# FX1 register map
Vendor: FTEL; File version: VP_FX1_V3.0_ISP_1.07
Registers are 32-bit, read-write, reset 0x0 unless marked. A register's access mark holds for its fields unless they carry their own. Offsets are from the block's base; [hi:lo] are bit positions; lines under a group give offsets from that group; {n}, {i} and the like mark numbered series; 'fields as' and 'values as' point back to an identical list.

## ISP (part 3 of 4) — ISP FX1 v1.07; đủ register/field từ sheet Flat Registers của CSR. Địa chỉ base theo BSP VP_FX1_V3.0; không thay thế xác nhận map silicon.
Base 0x11000000
0x2604 AF_ZONE_EN reset 0xFFFF — AF: focus zone mask (not implemented). The frame is divided into a 4x4 grid of zones; all sixteen zones always contribute. [access=rw]
  [15:0] ZONE_EN — Focus Zone Enable Mask (not implemented) No hardware behind this field; every zone is measured. One bit per focus zone, 4x4 grid in raster order. Reset enables all sixteen. bit 0 = ZONE_0 (Row 0, column 0) bit 1 = ZONE_1 (Row 0, column 1) bit 2 = ZONE_2 (Row 0, column 2) bit 3 = ZONE_3 (Row 0, column 3) bit 4 = ZONE_4 (Row 1, column 0) bit 5 = ZONE_5 (Row 1, column 1) bit 6 = ZONE_6 (Row 1, column 2) bit 7 = ZONE_7 (Row 1, column 3) bit 8 = ZONE_8 (Row 2, column 0) bit 9 = ZONE_9 (Row 2, column 1) bit 10 = ZONE_10 (Row 2, column 2) bit 11 = ZONE_11 (Row 2, column 3) bit 12 = ZONE_12 (Row 3, column 0) bit 13 = ZONE_13 (Row 3, column 1) bit 14 = ZONE_14 (Row 3, column 2) bit 15 = ZONE_15 (Row 3, column 3) [access=rw]
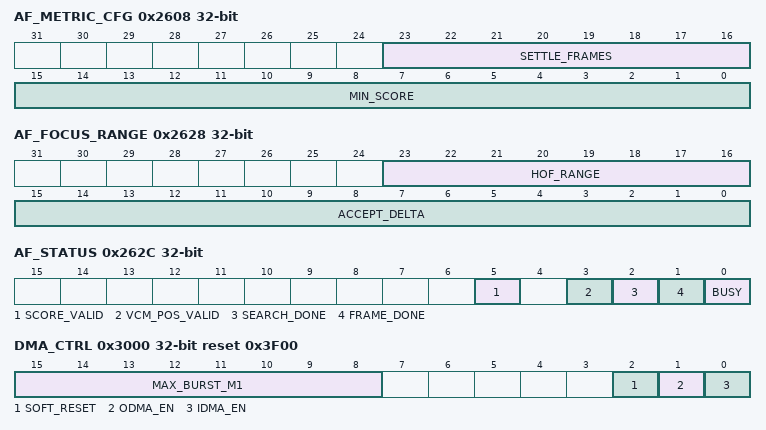
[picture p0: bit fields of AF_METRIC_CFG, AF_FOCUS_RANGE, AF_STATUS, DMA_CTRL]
0x2608 AF_METRIC_CFG — AF_METRIC_CFG: reserved autofocus search/lens-control field. This MAS provides per-zone focus measurements only; lens movement and search are software functions. [access=rw]
  [23:16] SETTLE_FRAMES — VCM Settling Frames (not implemented) Reserved; no processing effect in this MAS. [access=rw]
  [15:0] MIN_SCORE — Minimum Valid Focus Score (not implemented) Reserved; no processing effect in this MAS. [access=rw]
0x260C AF_STAT_ADDR — AF: which zone AF_STAT_DATA reports. [access=rw]
  [3:0] ZONE_ADDR — Readout Zone Select Zone index 0..15, raster order. [access=rw]
0x2610 AF_STAT_DATA ro — AF: low 32 bits of the selected focus sum from the leased result bank. Use the 64-bit port when the full value is needed. Higher scores indicate more local detail, not an absolute focus distance. [access=ro]
  [31:0] FOCUS_SCORE — Zone Focus Score Low 32 bits of the authoritative 64-bit focus sum selected by AF_STAT_ADDR. ACQUIRE before reading and RELEASE after copying; no lease returns zero and sets NO_LEASE. [access=ro]
0x2614 AF_LUT_ADDR — AF_LUT_ADDR: reserved autofocus search/lens-control field. This MAS provides per-zone focus measurements only; lens movement and search are software functions. [access=rw]
  [7:0] LUT_ADDR — Position LUT Index (not implemented) Reserved; no processing effect in this MAS. [access=rw]
0x2618 AF_LUT_DATA — AF_LUT_DATA: reserved autofocus search/lens-control field. This MAS provides per-zone focus measurements only; lens movement and search are software functions. [access=rw]
  [15:0] VCM_POSITION — Position LUT Data (not implemented) Reserved; no processing effect in this MAS. [access=rw]
0x261C AF_VCM_CUR_POS — AF_VCM_CUR_POS: reserved autofocus search/lens-control field. This MAS provides per-zone focus measurements only; lens movement and search are software functions. [access=rw]
  [15:0] VCM_CUR_POS — Current VCM Position (not implemented) Reserved; no processing effect in this MAS. Software that drives a VCM itself can still use it as a scratch tag. [access=rw]
0x2620 AF_VCM_BEST_POS ro — AF_VCM_BEST_POS: reserved autofocus search/lens-control field. This MAS provides per-zone focus measurements only; lens movement and search are software functions. [access=ro]
  [15:0] VCM_BEST_POS — Best VCM Position (not implemented) Reserved; no processing effect in this MAS. [access=ro]
0x2624 AF_PEAK_SCORE ro — AF_PEAK_SCORE: reserved autofocus search/lens-control field. This MAS provides per-zone focus measurements only; lens movement and search are software functions. [access=ro]
  [31:0] PEAK_SCORE — Peak Focus Score (not implemented) Reserved; no processing effect in this MAS. [access=ro]
0x2628 AF_FOCUS_RANGE — AF_FOCUS_RANGE: reserved autofocus search/lens-control field. This MAS provides per-zone focus measurements only; lens movement and search are software functions. [access=rw]
  [23:16] HOF_RANGE — Hyperfocal Range (not implemented) Reserved; no processing effect in this MAS. [access=rw]
  [15:0] ACCEPT_DELTA — Acceptable Focus Delta (not implemented) Reserved; no processing effect in this MAS. [access=rw]
0x262C AF_STATUS — AF: measurement status. BUSY reports in-flight accumulation, FRAME_DONE is a sticky W1C completion event, and SCORE_VALID identifies published scores. Search-related fields are reserved. [access=mixed]
  [5] SCORE_VALID ro — Focus Scores Valid 1 = the published scores are from a completed frame. [access=ro]
  [3] VCM_POS_VALID write-1-clears — VCM Position Valid (not implemented) Reserved; no processing effect in this MAS. [access=w1c]
  [2] SEARCH_DONE write-1-clears — Search Complete (not implemented) Reserved; no processing effect in this MAS. [access=w1c]
  [1] FRAME_DONE write-1-clears — Focus Scores Ready Set when a frame's focus scores are complete. Write 1 to clear. [access=w1c]
  [0] BUSY ro — AF Statistics Busy 1 = a frame is being accumulated. [access=ro]
0x2630 AF_CONTEXT_ID — AF: software lens-position context tag captured with the completed statistics frame. [access=rw]
  [31:0] CONTEXT_ID — Statistics Context Tag Arbitrary software value, captured with the frame that is measured next. Exposure and lens changes take effect some frames after they are requested, so the tag is how software tells which request a result belongs to: write it here before the frame it describes, and read it back from AF_RESULT_CONTEXT_ID alongside that frame's statistics. [access=rw]
0x2634 AF_RESULT_CONTEXT_ID ro — AF: software context tag published with the leased statistics frame; stable until RELEASE. [access=ro]
  [31:0] CONTEXT_ID — Captured Statistics Context Tag AF_CONTEXT_ID captured at ingress for the leased statistics frame. Stable until RELEASE, including when another frame completes. No lease returns zero and sets NO_LEASE. [access=ro]
0x2638 AF_FRAME_ID ro — AF: ingress frame identifier of the leased result bank, read-only. [access=ro]
  [31:0] FRAME_ID — Shared ingress-SOF frame number of the leased statistics. First admitted frame after hard reset is 1; wraps modulo 2^32. Common and DMA soft resets preserve the counter. Metadata remains stable until RELEASE; no lease returns zero and sets the ownership error. [access=ro]
0x2800 OFMT_CTRL — Output Formatter control. In the integrated core the formatter padding input is tied to zero: STRIDE_EN, OFMT_Y_STRIDE and OFMT_UV_STRIDE are readable storage with no effect, and ODMA alone applies the line stride. [access=rw]
  [0] STRIDE_EN — Line Stride Padding Enable Storage only in the integrated core; lines are always emitted packed and the ODMA applies the stride. Padding up to OFMT_Y_STRIDE / OFMT_UV_STRIDE is a standalone formatter capability. [access=rw]
0x2804 OFMT_Y_STRIDE reset 0xF00 — Output Formatter: luma line stride in bytes. Storage only in the integrated core (see OFMT_CTRL). [access=rw]
  [15:0] Y_STRIDE — Luma Line Stride Bytes from one luma line to the next, one byte per pixel. A value at or below the active width emits no padding. [access=rw]
0x2808 OFMT_UV_STRIDE reset 0xF00 — Output Formatter: chroma line stride in bytes. Storage only in the integrated core (see OFMT_CTRL). [access=rw]
  [15:0] UV_STRIDE — Chroma Line Stride Bytes from one chroma line to the next. Padding is emitted as 16-bit beats, so an odd byte count rounds down. [access=rw]
0x3000 DMA_CTRL reset 0x3F00 — DMA Engine: control at byte offset 0x3000. Configure and enable the pixel pipeline before arming/enabling DMA so output geometry is valid. DMA and CSR transactions are independent. [access=mixed]
  [15:8] MAX_BURST_M1 — Maximum AXI Burst Length Minus One Encoded value 0..255 gives 1..256 beats. Reset 63 gives 64 beats. MAX_BURST_BEATS in the MAS is the effective value MAX_BURST_M1+1; bursts also split at line and 4 KiB boundaries. [access=rw]
  [2] SOFT_RESET wo write-1-sets — DMA Soft Reset Request DMA-scope group recovery: stop admission, drain both AXI masters, held requests and internal consumers, then 15-clock internal reset pulse; reads zero. Preserves CSR configuration, the sealed active profile, completed READY/LEASED statistics and the DONE bits and metadata of outputs completed before the request. Preserves DMA_ERR and DMA_IRQ_STAT. Clears VALID/FREE ownership and restarts every rotation at buffer 0. Poll COMMON_RECOVERY_STATUS.BUSY/DONE; copy abort records before restart. Busy requests rejected with TUNE_ERROR.PENDING. COMMON_CTRL.SOFT_RST has the broader pipeline/result reset scope. [access=w1p]
  [1] ODMA_EN — Output DMA Enable 1 = the output DMA writes frames to DDR. [access=rw]
  [0] IDMA_EN — Input Enable 1 = the input path admits frames: the input DMA fetches frames from DDR (INPUT_SRC_CTRL.SEL = 0) or the AXI4-Stream adapter accepts frames from the stream port (SEL = 1). [access=rw]
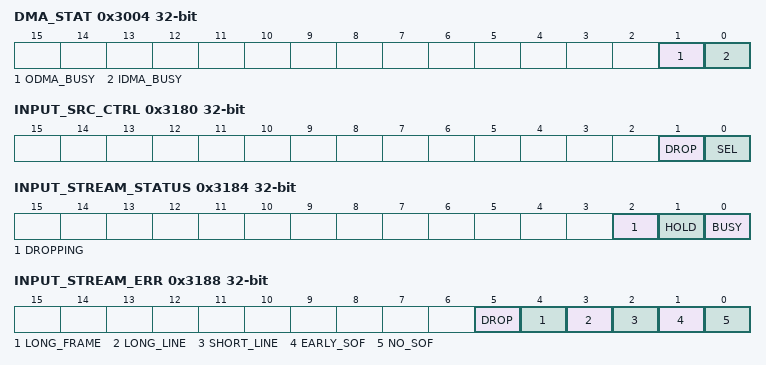
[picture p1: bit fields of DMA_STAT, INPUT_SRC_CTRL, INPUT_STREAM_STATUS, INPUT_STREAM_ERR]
0x3004 DMA_STAT ro — DMA Engine: engine status, read-only. Both bits read 0 on a wedged engine as well as an idle one, so do not treat 0 here as proof the engine is healthy -- check the frame counters advance. [access=ro]
  [1] ODMA_BUSY — Output DMA Busy 1 = the output DMA has a transfer outstanding. [access=ro]
  [0] IDMA_BUSY — Input Busy 1 = the input DMA has a transfer outstanding, or the AXI4-Stream adapter is forwarding a frame (SEL = 1). [access=ro]
0x3008 DMA_ERR write-1-clears — DMA Engine: sticky error flags. Write 1 to clear. Sticky so a fault that occurred mid-frame survives until software looks. [access=w1c]
  [5:0] ERR write-1-clears — Sticky DMA Error Flags W1C, hardware set wins over simultaneous clear. DMA-scope recovery, automatic or commanded, preserves these bits; only W1C, common recovery and hard reset clear them. Bit 0 ALIGN: illegal address/stride alignment or geometry, a base-address bit at or above the build address width, or a plane whose last byte reaches 2^ADDR_W; checked at IDMA frame start and ODMA buffer claim. The buffer is not used, its ownership bit clears and the rotation does not advance. Bit 1 IDMA_UNDERRUN: enabled idle input DMA has no valid head buffer (never with INPUT_SRC_CTRL.SEL = 1); stalls without dropping data. Bit 2 ODMA_OVERFLOW: pixels await an output buffer; backpressure at a line boundary until one is free. Bit 3 AXI_RD: terminal read response error; starts automatic DMA-scope recovery. Bit 4 AXI_WR: terminal write response error; starts automatic DMA-scope recovery. Bit 5 STREAM: AXI4-Stream input framing error or dropped frame; INPUT_STREAM_ERR holds the cause. The adapter repairs the frame; no recovery starts. [access=w1c]
0x300C DMA_IRQ_EN — DMA Engine: interrupt enable mask. Gates which DMA_IRQ_STAT bits reach the interrupt output; the status bits set regardless. [access=rw]
  [7:0] IRQ_EN — DMA Interrupt Enable Mask Mask gates the interrupt output, not sticky status. Bit 0 CFG_ERROR (illegal start configuration). Bit 1 IDMA_START. Bit 2 IDMA_DONE. Bit 3 IDMA_UNDERRUN. Bit 4 ODMA_DONE. Bit 5 ODMA_OVERFLOW. Bit 6 AXI_ERROR (either master). Bit 7 STREAM_ERROR (DMA_ERR.STREAM set). Bits 1 and 2 report the input frame start and completion for either input source. [access=rw]
0x3010 DMA_IRQ_STAT write-1-clears — DMA Engine: sticky interrupt status. Write 1 to clear. [access=w1c]
  [7:0] IRQ write-1-clears — DMA Interrupt Status Flags Sticky W1C; hardware set wins over simultaneous clear. DMA-scope recovery, automatic or commanded, preserves these bits; only W1C, common recovery and hard reset clear them. Bit 0 CFG_ERROR (illegal start configuration). Bit 1 IDMA_START. Bit 2 IDMA_DONE. Bit 3 IDMA_UNDERRUN. Bit 4 ODMA_DONE. Bit 5 ODMA_OVERFLOW. Bit 6 AXI_ERROR (either master). Bit 7 STREAM_ERROR (DMA_ERR.STREAM set). Bits 1 and 2 report the input frame start and completion for either input source. [access=w1c]
0x3020 IDMA_STRIDE reset 0x1E00 — DMA Engine: input line stride in bytes. Must be at least 2*input_width and aligned to the AXI bus-byte width. Input bases are aligned to the same width; Bayer crop origin X is a multiple of bus_bytes/2 pixels and Y is even. [access=rw]
  [31:0] IDMA_STRIDE — Input Line Stride Bytes between input lines. Reset 7680 bytes, sufficient for 3840 pixels at 2 bytes each; larger than the reset 1920-pixel line payload. [access=rw]
0x3024 IDMA_BUF_VALID write-1-sets — DMA Engine: input buffer ownership. Four buffers rotate between software and hardware. Software sets a bit to hand a filled buffer to the engine; the engine clears it when it has read the buffer and software may refill it. [access=w1s]
  [7:0] IDMA_BUF_VALID write-1-sets — Input Buffer Valid Flags One bit per input buffer; write 1 to hand a filled buffer to the engine. 7:4 unused -- the engine implements four buffers Bits at or above the build buffer count read zero and ignore writes. Hardware clears a bit when it has finished reading that buffer. bit 0 = BUFFER_0 (Address from IDMA_BUF_ADDR_L0/H0) bit 1 = BUFFER_1 bit 2 = BUFFER_2 bit 3 = BUFFER_3 [access=w1s]
0x3028 IDMA_FRAME_COUNT ro — DMA Engine: number of successfully retired input frames since reset, modulo 2^32. Frame retirement waits for enabled outputs and statistics. [access=ro]
  [31:0] IDMA_FRAME_COUNT — Input Frame Counter Counts successfully retired frames, including statistics-only frames; wraps modulo 2^32. [access=ro]
{0x3040+8i} IDMA_BUF_ADDR_L{i} (i=0..3) — DMA Engine: input buffer {i} base address, low word. [access=rw]
  [31:0] IDMA_BUF_ADDR{i}_LO — Input Buffer {i} Address, Low Word Bits [31:0] of the DDR address of the buffer's first pixel. Offsetting this within a larger image, together with IDMA_STRIDE, is how a crop window is expressed. [access=rw]
{0x3044+8i} IDMA_BUF_ADDR_H{i} (i=0..3) — DMA Engine: input buffer {i} base address, high word. [access=rw]
  [31:0] IDMA_BUF_ADDR{i}_HI — Input Buffer {i} Address, High Word Bits [63:32] of the DDR address. [access=rw]
0x3080 ODMA_Y_STRIDE reset 0xF00 — DMA Engine: luma plane line stride. Output is NV12: a full-resolution luma plane followed by an interleaved chroma plane at half height. [access=rw]
  [31:0] Y_STRIDE — Luma Line Stride Bytes from one luma line to the next; one byte per pixel, rounded up to the bus width. [access=rw]
0x3084 ODMA_UV_STRIDE reset 0xF00 — DMA Engine: chroma plane line stride. The chroma plane has half as many lines as the luma plane but the same number of bytes per line, since U and V are interleaved at half horizontal rate. [access=rw]
  [31:0] UV_STRIDE — Chroma Line Stride Bytes from one chroma line to the next. [access=rw]
0x3088 ODMA_BUF_FREE write-1-sets — DMA Engine: output-buffer ownership. Software sets a free bit to make a buffer available; nothing is captured then. When the channel next output frame starts, hardware claims the head buffer, captures its bases, strides and that frame geometry, and clears the bit. Completion sets ODMA_BUF_DONE after both planes and all write responses retire. [access=w1s]
  [7:0] ODMA_BUF_FREE write-1-sets — Output Buffer Free Flags Bits 3:0 identify the four buffers; bits 7:4 are unused. Bits at or above the build buffer count read zero and ignore writes. Write 1 to make a buffer available. Hardware clears the bit when the output frame claims the buffer. Acknowledge DONE before rearming FREE. With no free buffer the pipeline stalls and reports ODMA_OVERFLOW. [access=w1s]
0x308C ODMA_BUF_DONE write-1-clears — CH0: DMA Engine: completed output buffers, sticky W1C. After both NV12 planes and all enabled channels and statistics drain, publish DONE and metadata together at successful frame retirement. Clear DONE before returning a buffer through ODMA_BUF_FREE. [access=w1c]
  [7:0] ODMA_BUF_DONE write-1-clears — Output Buffer Done Flags Bits 3:0 identify buffers; bits 7:4 unused. Set only at successful frame retirement. Write 1 to acknowledge, then separately set FREE to permit reuse. A simultaneous completion wins over clear. [access=w1c]
0x3090 ODMA_FRAME_COUNT ro — CH0: DMA Engine: number of successfully retired frames with this output enabled, modulo 2^32. [access=ro]
  [31:0] ODMA_FRAME_COUNT — Output Frame Counter Counts successful frame retirements for this enabled channel; wraps modulo 2^32. [access=ro]
{0x30A0+0x10*i} ODMA_Y_ADDR_L{i} (i=0..3) — DMA Engine: luma buffer {i} base address, low word. [access=rw]
  [31:0] ODMA_Y_ADDR{i}_LO — Luma Buffer {i} Address, Low Word Bits [31:0] of the DDR address of the luma plane. [access=rw]
{0x30A4+0x10*i} ODMA_Y_ADDR_H{i} (i=0..3) — DMA Engine: luma buffer {i} base address, high word. [access=rw]
  [31:0] ODMA_Y_ADDR{i}_HI — Luma Buffer {i} Address, High Word Bits [63:32] of the DDR address. [access=rw]
{0x30A8+0x10*i} ODMA_UV_ADDR_L{i} (i=0..3) — DMA Engine: chroma buffer {i} base address, low word. [access=rw]
  [31:0] ODMA_UV_ADDR{i}_LO — Chroma Buffer {i} Address, Low Word Bits [31:0] of the DDR address of the chroma plane. Independent of the luma address, so the two planes need not be contiguous. [access=rw]
{0x30AC+0x10*i} ODMA_UV_ADDR_H{i} (i=0..3) — DMA Engine: chroma buffer {i} base address, high word. [access=rw]
  [31:0] ODMA_UV_ADDR{i}_HI — Chroma Buffer {i} Address, High Word Bits [63:32] of the DDR address. [access=rw]
{0x3100+4i} IDMA_BUF_TAG{i} (i=0..3) — DMA frame metadata for buffer {i}. Software-assigned frame tag. Program before setting IDMA_BUF_VALID; captured with the input frame and published with its completed output buffer. [access=rw]
  [31:0] TAG — Full 32-bit value for buffer {i}; hard-reset value zero. Software-assigned frame tag. Program before setting IDMA_BUF_VALID; captured with the input frame and published with its completed output buffer. [access=rw]
{0x3110+4i} IDMA_BUF_TS{i} (i=0..3) — DMA frame metadata for buffer {i}. 32-bit capture timestamp in the FRAME_COUNTER time base. Program before setting IDMA_BUF_VALID; copied with the frame tag. Account for modulo-2^32 wrap. [access=rw]
  [31:0] TIMESTAMP — Full 32-bit value for buffer {i}; hard-reset value zero. 32-bit capture timestamp in the FRAME_COUNTER time base. Program before setting IDMA_BUF_VALID; copied with the frame tag. Account for modulo-2^32 wrap. [access=rw]
{0x3120+4i} ODMA_BUF_TAG{i} ro (i=0..3) — DMA frame metadata for buffer {i}. Input-frame tag associated with this completed output buffer. Published when the output frame completes; buffer indices need not match the input indices. [access=ro]
  [31:0] TAG — Full 32-bit value for buffer {i}; hard-reset value zero. Input-frame tag associated with this completed output buffer. Published when the output frame completes; buffer indices need not match the input indices. [access=ro]
{0x3130+4i} ODMA_BUF_TS{i} ro (i=0..3) — DMA frame metadata for buffer {i}. Capture timestamp copied with the input-frame tag and published at output completion. Same core-clock time base as FRAME_COUNTER. [access=ro]
  [31:0] TIMESTAMP — Full 32-bit value for buffer {i}; hard-reset value zero. Capture timestamp copied with the input-frame tag and published at output completion. Same core-clock time base as FRAME_COUNTER. [access=ro]
{0x3140+4i} ODMA_BUF_SOF_TS{i} ro (i=0..3) — DMA frame metadata for buffer {i}. Core-clock timestamp latched at this output frame's start-of-frame and published at completion. Use with EOF_TS for the frame processing span. [access=ro]
  [31:0] TIMESTAMP — Full 32-bit value for buffer {i}; hard-reset value zero. Core-clock timestamp latched at this output frame's start-of-frame and published at completion. Use with EOF_TS for the frame processing span. [access=ro]
{0x3150+4i} ODMA_BUF_EOF_TS{i} ro (i=0..3) — DMA frame metadata for buffer {i}. Core-clock timestamp latched at this output frame's end-of-frame and published at completion. Subtract SOF_TS or capture TS modulo 2^32 for processing span or end-to-end latency. [access=ro]
  [31:0] TIMESTAMP — Full 32-bit value for buffer {i}; hard-reset value zero. Core-clock timestamp latched at this output frame's end-of-frame and published at completion. Subtract SOF_TS or capture TS modulo 2^32 for processing span or end-to-end latency. [access=ro]
0x3160 FRAME_COUNTER ro — DMA metadata time base: free-running 32-bit core-clock counter. Wraps modulo 2^32 (about 14.3 seconds at 300 MHz). [access=ro]
  [31:0] COUNTER — Core-clock counter; hard-reset value zero. Capture and output SOF/EOF timestamps use this time base. Software must account for wrap and interpret differences within an unambiguous interval. [access=ro]
0x3180 INPUT_SRC_CTRL — Input source: DDR through the input DMA, or the AXI4-Stream slave port. DMA_CTRL.IDMA_EN enables the input path for either source. IDLE update; input-domain: the stream source supplies no trailing parity row, so the active geometry is re-derived on a change. [access=rw]
  [1] DROP — Stream Admission Policy 0: hold the SOF beat (TREADY low) until the frame is admitted (reset). 1: discard a whole frame whose SOF arrives while the ISP cannot admit it; INPUT_STREAM_ERR.DROP sets and INPUT_STREAM_DROP_COUNT increments. Use 1 for live sources without flow control. [access=rw]
  [0] SEL — Input Source Select 0: the input DMA reads raw frames from DDR (IDMA_* registers, reset). 1: raw frames arrive on the AXI4-Stream slave port (TUSER = SOF, TLAST = end of line); the input DMA is idle and the IDMA buffer registers are ignored. IDLE update. [access=rw]
0x3184 INPUT_STREAM_STATUS ro — AXI4-Stream input adapter state, read-only. All bits read 0 while SEL = 0. [access=ro]
  [2] DROPPING — Frame Being Discarded 1 while the beats of a dropped frame are discarded. [access=ro]
  [1] HOLD — SOF Held 1 while an SOF beat waits for admission with DROP = 0. [access=ro]
  [0] BUSY — Frame In Progress 1 from the admitted SOF until the last beat of the frame (received, padded or completed) has been passed to the pipeline. [access=ro]
0x3188 INPUT_STREAM_ERR write-1-clears — AXI4-Stream input framing errors, sticky, write 1 to clear. The adapter repairs every error, so the pipeline always receives complete frames of the programmed geometry; any bit also sets DMA_ERR.STREAM. [access=w1c]
  [5] DROP write-1-clears — Frame Dropped With INPUT_SRC_CTRL.DROP = 1 an SOF arrived while the ISP could not admit a frame; the whole frame was discarded. [access=w1c]
  [4] LONG_FRAME write-1-clears — Long Frame Beats without TUSER followed a complete frame; they were discarded until the next SOF. [access=w1c]
  [3] LONG_LINE write-1-clears — Long Line No TLAST on the last column; the extra beats of the line were discarded up to and including the next TLAST. [access=w1c]
  [2] SHORT_LINE write-1-clears — Short Line TLAST arrived before the last column; the rest of the line was completed by repeating the sample two columns back (same CFA colour). [access=w1c]
  [1] EARLY_SOF write-1-clears — Short Frame TUSER arrived before the last line of the frame; the rest of the frame was completed with zero samples and the SOF starts the next frame. [access=w1c]
  [0] NO_SOF write-1-clears — Data Before SOF A beat without TUSER arrived outside a frame (before the first SOF or after a dropped frame); it was discarded. [access=w1c]
0x318C INPUT_STREAM_FRAME_COUNT ro — AXI4-Stream input: frames admitted from the stream since reset, modulo 2^32. [access=ro]
  [31:0] COUNT — Admitted Stream Frames Increments at each admitted SOF; cleared by hard reset and by the DMA engine reset of a recovery. [access=ro]
0x3190 INPUT_STREAM_DROP_COUNT ro — AXI4-Stream input: frames discarded by the admission policy since reset, modulo 2^32. [access=ro]
  [31:0] COUNT — Dropped Stream Frames Increments for each frame discarded with INPUT_SRC_CTRL.DROP = 1; cleared by hard reset and by the DMA engine reset of a recovery. [access=ro]
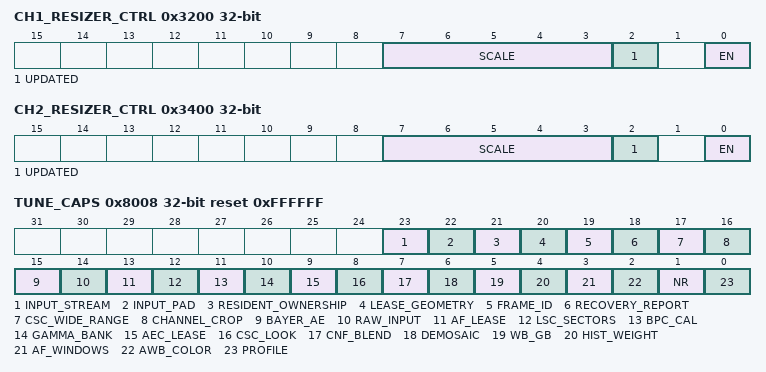
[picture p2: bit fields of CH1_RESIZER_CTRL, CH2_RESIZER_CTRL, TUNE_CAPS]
0x3200 CH1_RESIZER_CTRL — CH1 NV12 output resizer control, maximum output 3840x2160. Input is the post-IQ crop for this channel; the crop may be larger than the output. No upscaling or custom target sizes. Reject invalid targets before DMA arm; no silent FullRes fallback. Wait for channel OUT_W/H to settle. [access=rw]
  [7:3] SCALE — CH1 NV12 preset selector [7:3]. 0=FullRes crop bypass; 1..14 established presets; 16=640x640, 17=640x384, 18=640x352, 19=512x512, 20=416x416, 21=320x320. Codes 15 and 22..31 reserved. Maximum output 3840x2160. Output must not exceed crop dimensions. No upscaling. [access=rw]
  [2] UPDATED — Legacy software update hint; readable storage with no commit effect. Active size, crop, enable and SCALE changes trigger geometry derivation. Custom-size words are reserved. Wait for OUT_W/H to settle before arming DMA; capture geometry at SOF. [access=rw]
  [0] EN — CH1 resizer enable. 1 selects SCALE; 0 bypasses scaling and preserves crop size. Both paths must fit the 3840x2160 output limit. Change geometry only after stop/drain; validate before DMA arm. [access=rw]
0x3204 CH1_RESIZER_CUSTOM_W ro — Deprecated target-size address. Reserved in ABI 1.07; reads zero and ignores writes. Programmable custom resizing is not supported. [access=ro]
  [31:0] RESERVED — Reads zero; writes ignored. [access=ro]
0x3208 CH1_RESIZER_CUSTOM_H ro — Deprecated target-size address. Reserved in ABI 1.07; reads zero and ignores writes. Programmable custom resizing is not supported. [access=ro]
  [31:0] RESERVED — Reads zero; writes ignored. [access=ro]
0x3214 CH1_RESIZER_OUT_W ro — Validated derived output dimension. Reset zero; may retain the last completed value while geometry is invalid. Check the channel GEOMETRY_STATUS before arming DMA. [access=ro]
  [12:0] OUT_WIDTH
0x3218 CH1_RESIZER_OUT_H ro — Validated derived output dimension. Reset zero; may retain the last completed value while geometry is invalid. Check the channel GEOMETRY_STATUS before arming DMA. [access=ro]
  [12:0] OUT_HEIGHT
0x321C CH1_RESIZER_STATUS ro — RESIZER: block status. [access=ro]
  [0] BUSY — Resizer Busy 1 while the block itself holds pixels: the block's own busy, as defined in its MAS section. It can read 0 inside a frame (line fill, input gaps), so it does not show that a frame has drained; use COMMON_STATUS.BUSY = 0 for no frame in flight. This channel's resizer only. [access=ro]
0x3280 CH1_ODMA_Y_STRIDE reset 0xF00 — DMA Engine: luma plane line stride. Output is NV12: a full-resolution luma plane followed by an interleaved chroma plane at half height. [access=rw]
  fields as ODMA_Y_STRIDE
0x3284 CH1_ODMA_UV_STRIDE reset 0xF00 — DMA Engine: chroma plane line stride. The chroma plane has half as many lines as the luma plane but the same number of bytes per line, since U and V are interleaved at half horizontal rate. [access=rw]
  fields as ODMA_UV_STRIDE
0x3288 CH1_ODMA_BUF_FREE write-1-sets — CH1: DMA Engine: output-buffer ownership. Software sets a free bit before use; hardware clears it when the output frame starts. Completion sets ODMA_BUF_DONE after both planes and all write responses retire. [access=w1s]
  [7:0] ODMA_BUF_FREE write-1-sets — Output Buffer Free Flags Bits 3:0 identify the four buffers; bits 7:4 are unused. Write 1 to release a buffer to hardware. Hardware clears the bit at frame start. Acknowledge DONE before rearming FREE. With no free buffer the pipeline stalls and reports ODMA_OVERFLOW. [access=w1s]
0x328C CH1_ODMA_BUF_DONE write-1-clears — CH1: DMA Engine: completed output buffers, sticky W1C. After both NV12 planes and all enabled channels and statistics drain, publish DONE and metadata together at successful frame retirement. Clear DONE before returning a buffer through ODMA_BUF_FREE. [access=w1c]
  fields as ODMA_BUF_DONE
0x3290 CH1_ODMA_FRAME_COUNT ro — CH1: DMA Engine: number of successfully retired frames with this output enabled, modulo 2^32. [access=ro]
  fields as ODMA_FRAME_COUNT
{0x32A0+0x10*i} CH1_ODMA_Y_ADDR_L{i} (i=0..3) — DMA Engine: luma buffer {i} base address, low word. [access=rw]
  fields as ODMA_Y_ADDR_L0
{0x32A4+0x10*i} CH1_ODMA_Y_ADDR_H{i} (i=0..3) — DMA Engine: luma buffer {i} base address, high word. [access=rw]
  fields as ODMA_Y_ADDR_H0
{0x32A8+0x10*i} CH1_ODMA_UV_ADDR_L{i} (i=0..3) — DMA Engine: chroma buffer {i} base address, low word. [access=rw]
  fields as ODMA_UV_ADDR_L0
{0x32AC+0x10*i} CH1_ODMA_UV_ADDR_H{i} (i=0..3) — DMA Engine: chroma buffer {i} base address, high word. [access=rw]
  fields as ODMA_UV_ADDR_H0
{0x3300+4i} CH1_ODMA_BUF_TAG{i} ro (i=0..3) — CH1: DMA frame metadata for buffer {i}. Input-frame tag associated with this completed output buffer. Published when the output frame completes; buffer indices need not match the input indices. [access=ro]
  fields as ODMA_BUF_TAG0
{0x3310+4i} CH1_ODMA_BUF_TS{i} ro (i=0..3) — CH1: DMA frame metadata for buffer {i}. Capture timestamp copied with the input-frame tag and published at output completion. Same core-clock time base as FRAME_COUNTER. [access=ro]
  fields as ODMA_BUF_TS0
{0x3320+4i} CH1_ODMA_BUF_SOF_TS{i} ro (i=0..3) — CH1: DMA frame metadata for buffer {i}. Core-clock timestamp latched at this output frame's start-of-frame and published at completion. Use with EOF_TS for the frame processing span. [access=ro]
  fields as ODMA_BUF_SOF_TS0
{0x3330+4i} CH1_ODMA_BUF_EOF_TS{i} ro (i=0..3) — CH1: DMA frame metadata for buffer {i}. Core-clock timestamp latched at this output frame's end-of-frame and published at completion. Subtract SOF_TS or capture TS modulo 2^32 for processing span or end-to-end latency. [access=ro]
  fields as ODMA_BUF_EOF_TS0
0x3400 CH2_RESIZER_CTRL — CH2 AI RGB888 output resizer control, maximum output 640x640. Input is the post-IQ crop for this channel; the crop may be larger than the output. No upscaling or custom target sizes. Reject invalid targets before DMA arm; no silent FullRes fallback. Wait for channel OUT_W/H to settle. [access=rw]
  [7:3] SCALE — CH2 AI RGB888 preset selector [7:3]. 0=FullRes crop bypass; 8=640x360; 14=640x480; 16=640x640; 17=640x384; 18=640x352; 19=512x512; 20=416x416; 21=320x320. All other codes invalid on CH2. FullRes crop must fit 640x640. Output must not exceed crop dimensions. No upscaling. [access=rw]
  [2] UPDATED — Legacy software update hint; readable storage with no commit effect. Active size, crop, enable and SCALE changes trigger geometry derivation. Custom-size words are reserved. Wait for OUT_W/H to settle before arming DMA; capture geometry at SOF. [access=rw]
  [0] EN — CH2 resizer enable. 1 selects SCALE; 0 bypasses scaling and preserves crop size. Both paths must fit the 640x640 output limit. Change geometry only after stop/drain; validate before DMA arm. [access=rw]
0x3404 CH2_RESIZER_CUSTOM_W ro — Deprecated target-size address. Reserved in ABI 1.07; reads zero and ignores writes. Programmable custom resizing is not supported. [access=ro]
  [31:0] RESERVED — Reads zero; writes ignored. [access=ro]
0x3408 CH2_RESIZER_CUSTOM_H ro — Deprecated target-size address. Reserved in ABI 1.07; reads zero and ignores writes. Programmable custom resizing is not supported. [access=ro]
  [31:0] RESERVED — Reads zero; writes ignored. [access=ro]
0x3414 CH2_RESIZER_OUT_W ro — Validated derived output dimension. Reset zero; may retain the last completed value while geometry is invalid. Check the channel GEOMETRY_STATUS before arming DMA. [access=ro]
  [12:0] OUT_WIDTH
0x3418 CH2_RESIZER_OUT_H ro — Validated derived output dimension. Reset zero; may retain the last completed value while geometry is invalid. Check the channel GEOMETRY_STATUS before arming DMA. [access=ro]
  [12:0] OUT_HEIGHT
0x341C CH2_RESIZER_STATUS ro — RESIZER: block status. [access=ro]
  fields as CH1_RESIZER_STATUS
0x3480 CH2_ODMA_Y_STRIDE reset 0xF00 — CH2 packed RGB888 line stride in bytes. Historical Y name aliases the sole RGB plane; there is no CH2 UV plane. [access=rw]
  [31:0] Y_STRIDE — Bytes between packed RGB888 rows. At least 3*output_width, rounded up to a multiple of AXI bus bytes. Reset is 3840 bytes; padding bytes are not written. [access=rw]
0x3488 CH2_ODMA_BUF_FREE write-1-sets — CH2: DMA Engine: output-buffer ownership. Software sets a free bit before use; hardware clears it when the output frame starts. Completion sets ODMA_BUF_DONE after the packed RGB plane and all write responses retire. [access=w1s]
  fields as CH1_ODMA_BUF_FREE
0x348C CH2_ODMA_BUF_DONE write-1-clears — CH2: DMA Engine: completed output buffers, sticky W1C. After the single packed RGB plane and all enabled channels and statistics drain, publish DONE and metadata together at successful frame retirement. Clear DONE before returning a buffer through ODMA_BUF_FREE. [access=w1c]
  fields as ODMA_BUF_DONE
0x3490 CH2_ODMA_FRAME_COUNT ro — CH2: DMA Engine: number of successfully retired frames with this output enabled, modulo 2^32. [access=ro]
  fields as ODMA_FRAME_COUNT
{0x34A0+0x10*i} CH2_ODMA_Y_ADDR_L{i} (i=0..3) — CH2 packed RGB888 buffer {i} base address, low word. Historical Y name denotes the sole RGB plane. [access=rw]
  [31:0] ODMA_Y_ADDR{i}_LO — Bits [31:0] of the DDR base address of packed RGB888 buffer {i}. [access=rw]
{0x34A4+0x10*i} CH2_ODMA_Y_ADDR_H{i} (i=0..3) — CH2 packed RGB888 buffer {i} base address, high word. Historical Y name denotes the sole RGB plane. [access=rw]
  [31:0] ODMA_Y_ADDR{i}_HI — Bits [63:32] of the DDR base address of packed RGB888 buffer {i}. [access=rw]
{0x3500+4i} CH2_ODMA_BUF_TAG{i} ro (i=0..3) — CH2: DMA frame metadata for buffer {i}. Input-frame tag associated with this completed output buffer. Published when the output frame completes; buffer indices need not match the input indices. [access=ro]
  fields as ODMA_BUF_TAG0
{0x3510+4i} CH2_ODMA_BUF_TS{i} ro (i=0..3) — CH2: DMA frame metadata for buffer {i}. Capture timestamp copied with the input-frame tag and published at output completion. Same core-clock time base as FRAME_COUNTER. [access=ro]
  fields as ODMA_BUF_TS0
{0x3520+4i} CH2_ODMA_BUF_SOF_TS{i} ro (i=0..3) — CH2: DMA frame metadata for buffer {i}. Core-clock timestamp latched at this output frame's start-of-frame and published at completion. Use with EOF_TS for the frame processing span. [access=ro]
  fields as ODMA_BUF_SOF_TS0
{0x3530+4i} CH2_ODMA_BUF_EOF_TS{i} ro (i=0..3) — CH2: DMA frame metadata for buffer {i}. Core-clock timestamp latched at this output frame's end-of-frame and published at completion. Subtract SOF_TS or capture TS modulo 2^32 for processing span or end-to-end latency. [access=ro]
  fields as ODMA_BUF_EOF_TS0
0x8000 TUNE_ID ro reset 0x54554E45 — Extension identification. Zero on v1.04 unmapped address. Update: LIVE. MAS v1.07: tuning-profiles. [access=ro]
  [31:0] MAGIC — ASCII TUNE; only implemented extension hardware returns this value. [access=ro]
0x8004 TUNE_REV ro reset 0x10007 — Extension ABI revision 1.07; requires matching pipeline revision. [access=ro]
  [31:0] VALUE — Extension ABI 0x00010007. [access=ro]
0x8008 TUNE_CAPS ro reset 0xFFFFFF — Read-only capabilities. This build sets bits 0..23 (0x00FFFFFF). Without INPUT_PAD, the build uses legacy crop regardless of COMMON_INPUT_FORMAT.CROP. Unsupported features read zero; software checks the relevant bits before use. [access=ro]
  [23] INPUT_STREAM — AXI4-Stream raw input port with INPUT_SRC_CTRL source select, framing repair and admission policy. [access=ro]
  [22] INPUT_PAD — Input formatter supports default same-colour padding and selectable legacy crop. [access=ro]
  [21] RESIDENT_OWNERSHIP — Selected-resident EE readback and sealed resident protection [access=ro]
  [20] LEASE_GEOMETRY — Captured statistics geometry [access=ro]
  [19] FRAME_ID — Ingress identity on every successful output buffer [access=ro]
  [18] RECOVERY_REPORT — Observable recovery and four abort records [access=ro]
  [17] CSC_WIDE_RANGE — Range selected before single CSC YUV8 quantization. [access=ro]
  [16] CHANNEL_CROP — Independent crop and validated geometry readback. [access=ro]
  [15] BAYER_AE — BPC/DG RAW12 AE and leased source/domain metadata. [access=ro]
  [14] RAW_INPUT — Explicit RAW10/12 input normalization. [access=ro]
  [13] AF_LEASE — Implemented AF_LEASE capability. [access=ro]
  [12] LSC_SECTORS — Implemented LSC_SECTORS capability. [access=ro]
  [11] BPC_CAL — Implemented BPC_CAL capability. [access=ro]
  [10] GAMMA_BANK — Implemented GAMMA_BANK capability. [access=ro]
  [9] AEC_LEASE — Implemented AEC_LEASE capability. [access=ro]
  [8] CSC_LOOK — Implemented CSC_LOOK capability. [access=ro]
  [7] CNF_BLEND — Implemented CNF_BLEND capability. [access=ro]
  [6] DEMOSAIC — Implemented DEMOSAIC capability. [access=ro]
  [5] WB_GB — Implemented WB_GB capability. [access=ro]
  [4] HIST_WEIGHT — Implemented HIST_WEIGHT capability. [access=ro]
  [3] AF_WINDOWS — Implemented AF_WINDOWS capability. [access=ro]
  [2] AWB_COLOR — Implemented AWB_COLOR capability. [access=ro]
  [1] NR — Implemented NR capability. [access=ro]
  [0] PROFILE — Implemented PROFILE capability. [access=ro]
0x800C TUNE_MODE — Stopped-and-drained profile-mode selection. Legacy mode retains local update rules but uses the v1.06/v1.07 numeric domain. [access=rw]
  [0] ENABLE — 0 legacy; 1 extension. Change only after full pipeline drain with no leased statistics bank; otherwise rejected with MODE. Leaving profile mode after drain clears both seals, resident pins, active/pending state and bank-local payload readiness. [access=rw]
0x8010 TUNE_BANK — Live programming/readback selector. Selecting a sealed, active, pending or referenced bank is legal. Only mutations of its protected contents are rejected with LOCKED. [access=rw]
  [0] VALUE
0x8014 TUNE_PROFILE_ID — Software profile identifier stored in the selected bank. Zero is allowed. Update: PROFILE. MAS v1.07: tuning-profiles. [access=rw]
  [31:0] VALUE — Software profile identifier stored in the selected bank. Zero is allowed. External: the value is held outside the CSR block; the type is the bus behaviour. [access=rw]
0x8018 TUNE_APPLY_FRAME — Exact target ingress frame sequence when EXACT=1; otherwise ignored. Update: LIVE. MAS v1.07: tuning-profiles. [access=rw]
  [31:0] VALUE — Exact target ingress frame sequence when EXACT=1; otherwise ignored. [access=rw]
